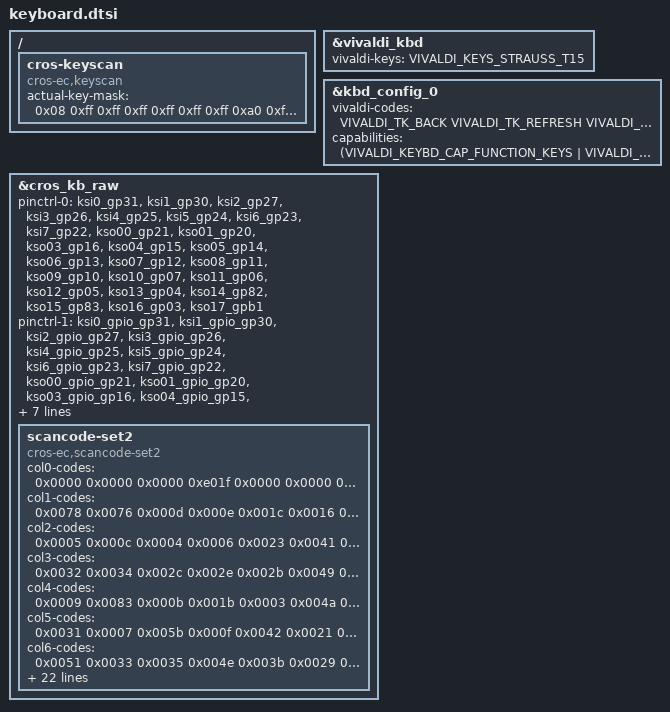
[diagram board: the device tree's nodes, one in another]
/* Copyright 2024 The ChromiumOS Authors
 * Use of this source code is governed by a BSD-style license that can be
 * found in the LICENSE file.
 */

/ {
	cros-keyscan {
		compatible = "cros-ec,keyscan";
		actual-key-mask = <
			0x08  /* C0 */
			0xff  /* C1 */
			0xff  /* C2 */
			0xff  /* C3 */
			0xff  /* C4 */
			0xff  /* C5 */
			0xff  /* C6 */
			0xa0  /* C7 */
			0xff  /* C8 */
			0xff  /* C9 */
			0x01  /* C10 */
			0xff  /* C11 */
			0xff  /* C12 */
			0x40  /* C13 */
			0x0a  /* C14 */
			0x40  /* C15 */
			0x03  /* C16 */
			0xc6  /* C17 */
		>;
	};
};

&vivaldi_kbd {
	vivaldi-keys = <VIVALDI_KEYS_STRAUSS_T15>;
};

&kbd_config_0 {
	vivaldi-codes = <
		VIVALDI_TK_BACK             /* T1 */
		VIVALDI_TK_REFRESH          /* T2 */
		VIVALDI_TK_FULLSCREEN       /* T3 */
		VIVALDI_TK_OVERVIEW         /* T4 */
		VIVALDI_TK_SNAPSHOT         /* T5 */
		VIVALDI_TK_BRIGHTNESS_DOWN  /* T6 */
		VIVALDI_TK_BRIGHTNESS_UP    /* T7 */
		VIVALDI_TK_DICTATE          /* T8 */
		VIVALDI_TK_ACCESSIBILITY    /* T9 */
		VIVALDI_TK_PLAY_PAUSE       /* T10 */
		VIVALDI_TK_MICMUTE          /* T11 */
		VIVALDI_TK_VOL_MUTE         /* T12 */
		VIVALDI_TK_VOL_DOWN         /* T13 */
		VIVALDI_TK_VOL_UP           /* T14 */
	>;
	capabilities = <(VIVALDI_KEYBD_CAP_FUNCTION_KEYS |
			VIVALDI_KEYBD_CAP_SCRNLOCK_KEY |
			VIVALDI_KEYBD_CAP_ASSISTANT_KEY)>;
};

&cros_kb_raw {
	status = "okay";
	/* No KSO2 (it's inverted and implemented by GPIO) */
	pinctrl-0 = <
		&ksi0_gp31
		&ksi1_gp30
		&ksi2_gp27
		&ksi3_gp26
		&ksi4_gp25
		&ksi5_gp24
		&ksi6_gp23
		&ksi7_gp22
		&kso00_gp21
		&kso01_gp20
		&kso03_gp16
		&kso04_gp15
		&kso05_gp14
		&kso06_gp13
		&kso07_gp12
		&kso08_gp11
		&kso09_gp10
		&kso10_gp07
		&kso11_gp06
		&kso12_gp05
		&kso13_gp04
		&kso14_gp82
		&kso15_gp83
		&kso16_gp03
		&kso17_gpb1
	>;
	pinctrl-1 = <
		&ksi0_gpio_gp31
		&ksi1_gpio_gp30
		&ksi2_gpio_gp27
		&ksi3_gpio_gp26
		&ksi4_gpio_gp25
		&ksi5_gpio_gp24
		&ksi6_gpio_gp23
		&ksi7_gpio_gp22
		&kso00_gpio_gp21
		&kso01_gpio_gp20
		&kso03_gpio_gp16
		&kso04_gpio_gp15
		&kso05_gpio_gp14
		&kso06_gpio_gp13
		&kso07_gpio_gp12
		&kso08_gpio_gp11
		&kso09_gpio_gp10
		&kso10_gpio_gp07
		&kso11_gpio_gp06
		&kso12_gpio_gp05
		&kso13_gpio_gp04
		&kso14_gpio_gp82
		&kso15_gpio_gp83
		&kso16_gpio_gp03
		&kso17_gpio_gpb1
	>;
	pinctrl-names = "default", "sleep";

	scancode-set2 {
		compatible = "cros-ec,scancode-set2";
		col0-codes  = <0x0000 0x0000 0x0000 0xe01f 0x0000 0x0000 0x0000 0x0000>;
		col1-codes  = <0x0078 0x0076 0x000d 0x000e 0x001c 0x0016 0x001a 0x003c>;
		col2-codes  = <0x0005 0x000c 0x0004 0x0006 0x0023 0x0041 0x0026 0x0043>;
		col3-codes  = <0x0032 0x0034 0x002c 0x002e 0x002b 0x0049 0x0025 0x0044>;
		col4-codes  = <0x0009 0x0083 0x000b 0x001b 0x0003 0x004a 0x001e 0x004d>;
		col5-codes  = <0x0031 0x0007 0x005b 0x000f 0x0042 0x0021 0x003e 0x0015>;
		col6-codes  = <0x0051 0x0033 0x0035 0x004e 0x003b 0x0029 0x0045 0x001d>;
		col7-codes  = <0x0000 0x0000 0x0000 0x0000 0x0000 0x0012 0x0000 0x0059>;
		col8-codes  = <0x0055 0x0052 0x0054 0x0036 0x004c 0x0022 0x003d 0x0024>;
		col9-codes  = <0xe06c 0x0001 0xe071 0x002f 0x004b 0x002a 0x0046 0x002d>;
		col10-codes = <0xe011 0x0000 0x006a 0x0000 0x005d 0x0000 0x0000 0x0000>;
		col11-codes = <0x0017 0x0066 0x000a 0x005d 0x005a 0x003a 0xe072 0xe075>;
		col12-codes = <0x001f 0x0064 0xe07d 0x0067 0xe069 0xe07a 0xe074 0xe06b>;
		col13-codes = <0x0000 0x0000 0x0000 0x0000 0x0000 0x0000 0x0011 0x0000>;
		col14-codes = <0x0000 0x0014 0x0000 0xe014 0x0000 0x0000 0x0000 0x0000>;
		col15-codes = <0x0000 0x0000 0x0000 0x0000 0x0000 0x0000 0x0027 0x0000>;
		col16-codes = <0x0037 0x0037 0x0000 0x0000 0x0000 0x0000 0x0000 0x0000>;
		col17-codes = <0x0000 0x0000 0x006a 0x0000 0x0000 0x0000 0x005d 0x0061>;
	};
};
